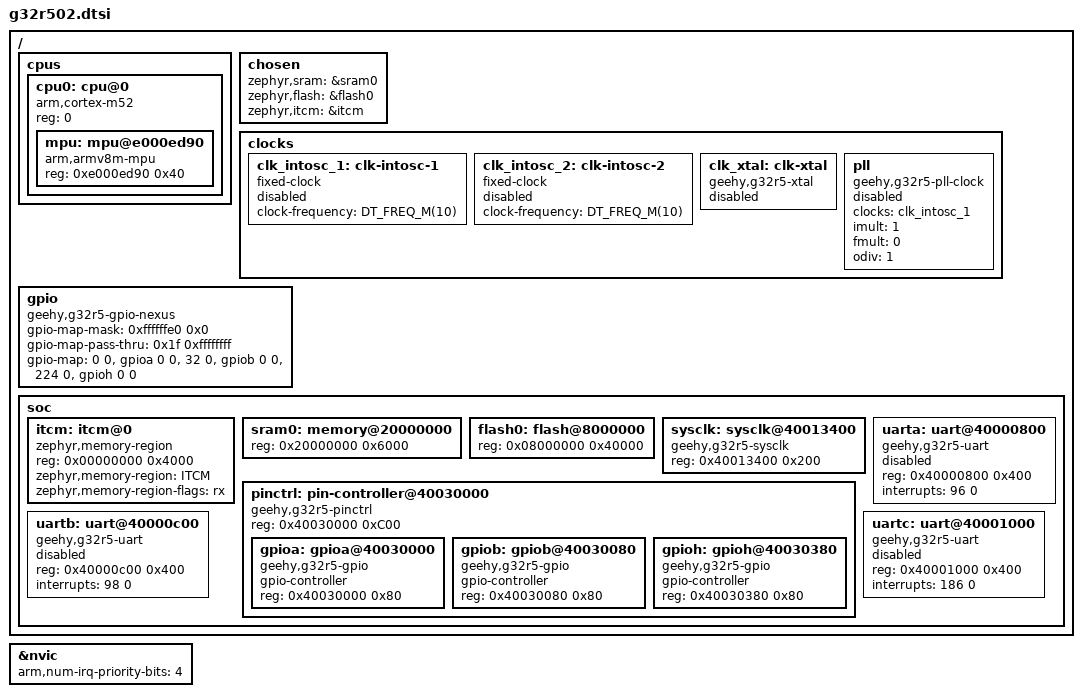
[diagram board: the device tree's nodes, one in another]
/*
 * Copyright (c) 2025 Quincy.W <wangqyfm@foxmail.com>
 *
 * SPDX-License-Identifier: Apache-2.0
 *
 * G32R502 is single-core only. No cpuclusters, no __CORE_CPU0__/__CORE_CPU1__.
 * SDK g32r502xc_itcm_ram.ld: Flash 256 KiB @ 0x08000000,
 * ITCM 16 KiB @ 0x0, DTCM 24 KiB @ 0x20000000.
 *
 * Peripheral bases differ from G32R501:
 * CLKCFG/sysclk 0x40013400, UARTA 0x40000800, UARTB 0x40000C00,
 * UARTC 0x40001000. GPIOCTRL is the same 0x40030000 as G32R501.
 */

#include <arm/armv8.1-m.dtsi>
#include <zephyr/dt-bindings/gpio/gpio.h>
#include <freq.h>
#include <mem.h>

/ {
	cpus {
		#address-cells = <1>;
		#size-cells = <0>;

		cpu0: cpu@0 {
			compatible = "arm,cortex-m52";
			reg = <0>;
			#address-cells = <1>;
			#size-cells = <1>;

			mpu: mpu@e000ed90 {
				compatible = "arm,armv8m-mpu";
				reg = <0xe000ed90 0x40>;
			};
		};
	};

	chosen {
		zephyr,sram = &sram0;
		zephyr,flash = &flash0;
		zephyr,itcm = &itcm;
	};

	clocks {
		clk_intosc_1: clk-intosc-1 {
			compatible = "fixed-clock";
			#clock-cells = <0>;
			clock-frequency = <DT_FREQ_M(10)>;
			status = "disabled";
		};

		clk_intosc_2: clk-intosc-2 {
			compatible = "fixed-clock";
			#clock-cells = <0>;
			clock-frequency = <DT_FREQ_M(10)>;
			status = "disabled";
		};

		clk_xtal: clk-xtal {
			compatible = "geehy,g32r5-xtal";
			#clock-cells = <0>;
			status = "disabled";
		};

		pll: pll {
			compatible = "geehy,g32r5-pll-clock";
			#clock-cells = <0>;
			clocks = <&clk_intosc_1>;
			imult = <1>;
			fmult = <0>;
			odiv = <1>;
			status = "disabled";
		};
	};

	gpio: gpio {
		compatible = "geehy,g32r5-gpio-nexus";
		#gpio-cells = <2>;
		gpio-map-mask = <0xffffffe0 0x0>;
		gpio-map-pass-thru = <0x1f 0xffffffff>;
		gpio-map = <0 0 &gpioa 0 0>,
			   <32 0 &gpiob 0 0>,
			   <224 0 &gpioh 0 0>;
	};

	soc {
		itcm: itcm@0 {
			compatible = "zephyr,memory-region";
			reg = <0x00000000 0x4000>;
			zephyr,memory-region = "ITCM";
			zephyr,memory-region-flags = "rx";
			status = "okay";
		};

		sram0: memory@20000000 {
			reg = <0x20000000 0x6000>;
		};

		flash0: flash@8000000 {
			reg = <0x08000000 0x40000>;
		};

		sysclk: sysclk@40013400 {
			compatible = "geehy,g32r5-sysclk";
			#clock-cells = <0>;
			reg = <0x40013400 0x200>;
		};

		pinctrl: pin-controller@40030000 {
			compatible = "geehy,g32r5-pinctrl";
			#address-cells = <1>;
			#size-cells = <1>;
			reg = <0x40030000 0xC00>;

			gpioa: gpioa@40030000 {
				compatible = "geehy,g32r5-gpio";
				gpio-controller;
				#gpio-cells = <2>;
				reg = <0x40030000 0x80>;
			};

			gpiob: gpiob@40030080 {
				compatible = "geehy,g32r5-gpio";
				gpio-controller;
				#gpio-cells = <2>;
				reg = <0x40030080 0x80>;
			};

			gpioh: gpioh@40030380 {
				compatible = "geehy,g32r5-gpio";
				gpio-controller;
				#gpio-cells = <2>;
				reg = <0x40030380 0x80>;
			};
		};

		uarta: uart@40000800 {
			compatible = "geehy,g32r5-uart";
			reg = <0x40000800 0x400>;
			interrupts = <96 0>;
			status = "disabled";
		};

		uartb: uart@40000c00 {
			compatible = "geehy,g32r5-uart";
			reg = <0x40000c00 0x400>;
			interrupts = <98 0>;
			status = "disabled";
		};

		uartc: uart@40001000 {
			compatible = "geehy,g32r5-uart";
			reg = <0x40001000 0x400>;
			interrupts = <186 0>;
			status = "disabled";
		};
	};
};

&nvic {
	arm,num-irq-priority-bits = <4>;
};
